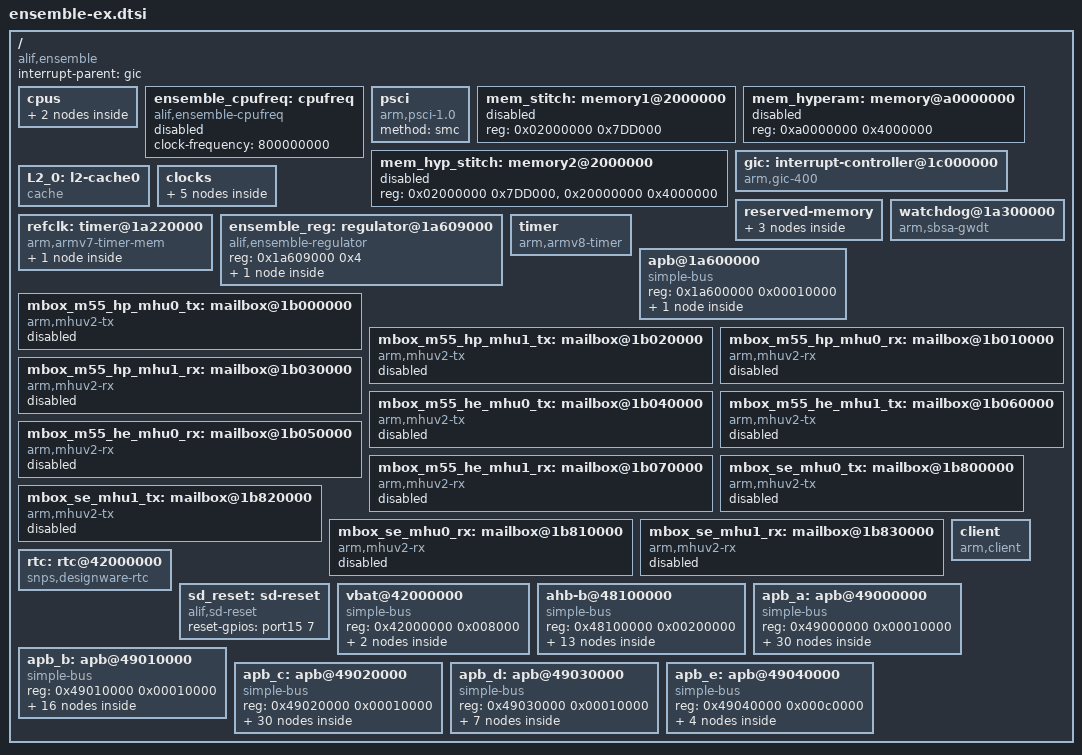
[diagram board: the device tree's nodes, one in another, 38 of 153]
// SPDX-License-Identifier: GPL-2.0+
/*
 * Copyright (C) 2025 Alif Semiconductor
 */
#include <dt-bindings/interrupt-controller/arm-gic.h>
#include <dt-bindings/pinctrl/alif,ensemble-pinfunc.h>
#include <dt-bindings/clock/alif,ensemble-clock.h>
#include <dt-bindings/gpio/gpio.h>
#include "devkit_ex_dct_defines.h"
/ {
	compatible = "alif,ensemble";
	interrupt-parent = <&gic>;
	#address-cells = <1>;
	#size-cells = <1>;

	cpus {
		#address-cells = <1>;
		#size-cells = <0>;

		cpu0: cpu@0 {
			compatible = "arm,armv8";
			reg = <0>;
			device_type = "cpu";
			enable-method = "psci";
			next-level-cache = <&L2_0>;
		};

		cpu1: cpu@1 {
			compatible = "arm,armv8";
			reg = <1>;
			device_type = "cpu";
			enable-method = "psci";
			next-level-cache = <&L2_0>;
			status = "disabled";
		};
	};

	ensemble_cpufreq: cpufreq {
		compatible = "alif,ensemble-cpufreq";
		clock-frequency = <800000000>;  /* 800 MHz boot default */
		status = "disabled";
	};

	psci {
		compatible = "arm,psci-1.0";
		method = "smc";
	};

	mem_stitch: memory1@2000000 {
		device_type = "memory";
		reg = <0x02000000 0x7DD000>;
		status = "disabled";
			/* 0x1000 @ 0x027DD000 reserved for IPC shared memory */
			/* 0x20000 @ 0x027DE000 reserved for arm-tf */
			/* 0x1000 @ 0x027FE000 reserved for MHU services */
	};

	mem_hyperam: memory@a0000000 {
		device_type = "memory";
		reg = <0xa0000000 0x4000000>;
		status = "disabled";
			/* 0x1000 @ 0x027DD000 reserved for IPC shared memory */
			/* 0x20000 @ 0x027DE000 reserved for arm-tf */
			/* 0x1000 @ 0x027FE000 reserved for MHU services */
	};

	mem_hyp_stitch: memory2@2000000 {
		device_type = "memory";
		reg = <0x02000000 0x7DD000>,
			<0x20000000 0x4000000>;
		status = "disabled";
			/* 0x1000 @ 0x027DD000 reserved for IPC shared memory */
			/* 0x20000 @ 0x027DE000 reserved for arm-tf */
			/* 0x1000 @ 0x027FE000 reserved for MHU services */
	};

	gic: interrupt-controller@1c000000 {
		compatible = "arm,gic-400";
		#interrupt-cells = <3>;
		#address-cells = <0>;
		interrupt-controller;
		reg =	<0x1c010000 0x1000>,
			<0x1c02f000 0x2000>,
			<0x1c04f000 0x1000>,
			<0x1c06f000 0x2000>;
		interrupts = <1 9 0xf08>;
	};

	L2_0: l2-cache0 {
		compatible = "cache";
	};

	clocks {
		hfxo: clock-38m4 {
			compatible = "fixed-clock";
			#clock-cells = <0>;
			clock-frequency = <38400000>;
			clock-output-names = "hfxo";
		};

		pll_clk1: clock-800m {
			compatible = "fixed-clock";
			#clock-cells = <0>;
			clock-frequency = <800000000>;
			clock-output-names = "pll_clk1";
		};

		pll_clk3: clock-480m {
			compatible = "fixed-clock";
			#clock-cells = <0>;
			clock-frequency = <480000000>;
			clock-output-names = "pll_clk3";
		};

		ext_clk: clock-20m {
			compatible = "fixed-clock";
			#clock-cells = <0>;
			clock-frequency = <20000000>;
			clock-output-names = "ext_clk";
		};
		wm8904_mclk: clock-12m288 {
			compatible = "fixed-clock";
			#clock-cells = <0>;
			clock-frequency = <12288000>;
			clock-output-names = "wm8904_mclk";
		};
	};

	reserved-memory {
		#address-cells = <1>;
		#size-cells = <1>;
		ranges;

		/* Reserved memory for Ethos-U85 NPU operations - WITHIN HyperRAM */
		ethosu_reserved: ethosu@a2000000 {
			compatible = "shared-dma-pool";
			reg = <0xa2000000 0x1000000>; /* 16MB within HyperRAM */
			no-map;
		};

		/* Ethos-U85 dedicated SRAM pool */
		ethosu_sram: ethosu_sram@a3000000 {
			compatible = "shared-dma-pool";
			reg = <0xa3000000 0x60000>; /* 384KB SRAM within HyperRAM */
			no-map;
		};

		/* CPI frame buffer pool in on-chip SRAM (4 x 560x560 RAW10 frames) */
		cpi_buf: cpi-frame-buffer@2000000 {
			compatible = "shared-dma-pool";
			reg = <0x02000000 0x300000>; /* 3MB from SRAM */
			no-map;
		};

	};

	refclk: timer@1a220000 {
		compatible = "arm,armv7-timer-mem";
		reg = <0x1a220000  0x1000>;
		clock-frequency = <100000000>;
		#address-cells = <1>;
		#size-cells = <1>;
		ranges;

		frame@1a230000 {
			frame-number = <0>;
			interrupts = <0 2 0xf04>;
			reg = <0x1a230000 0x1000>;
		};
	};

	ensemble_reg: regulator@1a609000 {
		compatible = "alif,ensemble-regulator";
		reg = <0x1a609000 0x4>;
		flexio_reg: ensemble_flexio {
			regulator-name = "ensemble_flexio";
			regulator-min-microvolt = <1800000>;
			regulator-max-microvolt = <3300000>;
			regulator-initial-mode = <0x4>;
			regulator-always-on;
		};
	};

	watchdog@1a300000 {
		compatible = "arm,sbsa-gwdt";
		reg = <0x1a300000 0x1000>,
			<0x1a310000 0x1000>;
		clocks = <&psclks ENSEMBLE_SYST_PCLK>;
		clock-names = "syst_pclk";
		interrupt-parent = <&gic>;
		interrupts = <0 32 4>;
		timeout-sec = <100>;
	};

	timer {
		compatible = "arm,armv8-timer";
		interrupts =	<GIC_PPI 13 (GIC_CPU_MASK_SIMPLE(2) |
					 IRQ_TYPE_LEVEL_LOW)>,
				<GIC_PPI 14 (GIC_CPU_MASK_SIMPLE(2) |
					 IRQ_TYPE_LEVEL_LOW)>,
				<GIC_PPI 11 (GIC_CPU_MASK_SIMPLE(2) |
					 IRQ_TYPE_LEVEL_LOW)>,
				<GIC_PPI 10 (GIC_CPU_MASK_SIMPLE(2) |
					 IRQ_TYPE_LEVEL_LOW)>;
		arm,cpu-registers-not-fw-configured;
	};

	apb@1a600000 {
		compatible = "simple-bus";
		#address-cells = <1>;
		#size-cells = <1>;
		reg = <0x1a600000 0x00010000>;
		ranges = <>;

		pinmux: pinctrl@1a603000 {
			compatible = "alif,ensemble-pinctrl";
			reg = <0x1a603000 0x00001000>;
		};
	};

	mbox_m55_hp_mhu0_tx: mailbox@1b000000 {
		compatible = "arm,mhuv2-tx","arm,primecell";
		reg = <0x1b000000 0x1000>;
		clocks = <&psclks ENSEMBLE_SYST_ACLK>;
		clock-names = "apb_pclk";
		interrupts = <0 11 4>;
		interrupt-names = "mhu_tx";
		arm,mhuv2-protocols = <1 1>, <1 1>;
		#mbox-cells = <2>;
		mbox-name = "arm-m55_hp-mhu0_tx";
		status = "disabled";
	};
	mbox_m55_hp_mhu1_tx: mailbox@1b020000 {
		compatible = "arm,mhuv2-tx","arm,primecell";
		reg = <0x1b020000 0x1000>;
		clocks = <&psclks ENSEMBLE_SYST_ACLK>;
		clock-names = "apb_pclk";
		interrupts = <0 46 4>;
		interrupt-names = "mhu_tx";
		arm,mhuv2-protocols = <1 1>, <1 1>;
		#mbox-cells = <2>;
		mbox-name = "arm-m55_hp-mhu1_tx";
		status = "disabled";
	};
	mbox_m55_hp_mhu0_rx: mailbox@1b010000 {
		compatible = "arm,mhuv2-rx","arm,primecell";
		reg = <0x1b010000 0x1000>;
		clocks = <&psclks ENSEMBLE_SYST_ACLK>;
		clock-names = "apb_pclk";
		interrupts = <0 12 4>;
		interrupt-names = "mhu_rx";
		arm,mhuv2-protocols = <1 1>, <1 1>;
		#mbox-cells = <2>;
		mbox-name = "arm-m55_hp-mhu0_rx";
		status = "disabled";
	};
	mbox_m55_hp_mhu1_rx: mailbox@1b030000 {
		compatible = "arm,mhuv2-rx","arm,primecell";
		reg = <0x1b030000 0x1000>;
		clocks = <&psclks ENSEMBLE_SYST_ACLK>;
		clock-names = "apb_pclk";
		interrupts = <0 47 4>;
		interrupt-names = "mhu_rx";
		arm,mhuv2-protocols = <1 1>, <1 1>;
		#mbox-cells = <2>;
		mbox-name = "arm-m55_hp-mhu1_rx";
		status = "disabled";
	};

	mbox_m55_he_mhu0_tx: mailbox@1b040000 {
		compatible = "arm,mhuv2-tx","arm,primecell";
		reg = <0x1b040000 0x1000>;
		clocks = <&psclks ENSEMBLE_SYST_ACLK>;
		clock-names = "apb_pclk";
		interrupts = <0 13 4>;
		interrupt-names = "mhu_tx";
		arm,mhuv2-protocols = <1 1>, <1 1>;
		#mbox-cells = <2>;
		mbox-name = "arm-m55_he-mhu0_tx";
		status = "disabled";
	};
	mbox_m55_he_mhu1_tx: mailbox@1b060000 {
		compatible = "arm,mhuv2-tx","arm,primecell";
		reg = <0x1b060000 0x1000>;
		clocks = <&psclks ENSEMBLE_SYST_ACLK>;
		clock-names = "apb_pclk";
		interrupts = <0 48 4>;
		interrupt-names = "mhu_tx";
		arm,mhuv2-protocols = <1 1>, <1 1>;
		#mbox-cells = <2>;
		mbox-name = "arm-m55_he-mhu1_tx";
		status = "disabled";
	};
	mbox_m55_he_mhu0_rx: mailbox@1b050000 {
		compatible = "arm,mhuv2-rx","arm,primecell";
		reg = <0x1b050000 0x1000>;
		clocks = <&psclks ENSEMBLE_SYST_ACLK>;
		clock-names = "apb_pclk";
		interrupts = <0 14 4>;
		interrupt-names = "mhu_rx";
		arm,mhuv2-protocols = <1 1>, <1 1>;
		#mbox-cells = <2>;
		mbox-name = "arm-m55_he-mhu0_rx";
		status = "disabled";
	};
	mbox_m55_he_mhu1_rx: mailbox@1b070000 {
		compatible = "arm,mhuv2-rx","arm,primecell";
		reg = <0x1b070000 0x1000>;
		clocks = <&psclks ENSEMBLE_SYST_ACLK>;
		clock-names = "apb_pclk";
		interrupts = <0 49 4>;
		interrupt-names = "mhu_rx";
		arm,mhuv2-protocols = <1 1>, <1 1>;
		#mbox-cells = <2>;
		mbox-name = "arm-m55_he-mhu1_rx";
		status = "disabled";
	};
	mbox_se_mhu0_tx: mailbox@1b800000 {
		#mbox-cells = <2>;
		compatible = "arm,mhuv2-tx","arm,primecell";
		reg = <0x1b800000 0x1000>;
		clocks = <&psclks ENSEMBLE_SYST_ACLK>;
		clock-names = "apb_pclk";
		interrupts = <0 9 4>;
		interrupt-names = "mhu_tx";
		arm,mhuv2-protocols = <1 1>, <1 1>;
		mbox-name = "arm-se-mhu0_tx";
		status = "disabled";
	};

	mbox_se_mhu1_tx: mailbox@1b820000 {
		compatible = "arm,mhuv2-tx","arm,primecell";
		reg = <0x1b820000 0x1000>;
		clocks = <&psclks ENSEMBLE_SYST_ACLK>;
		clock-names = "apb_pclk";
		interrupts = <0 44 4>;
		interrupt-names = "mhu_tx";
		arm,mhuv2-protocols = <1 1>, <1 1>;
		#mbox-cells = <2>;
		mbox-name = "arm-se-mhu1_tx";
		status = "disabled";
	};
	mbox_se_mhu0_rx: mailbox@1b810000 {
		#mbox-cells = <2>;
		compatible = "arm,mhuv2-rx","arm,primecell";
		reg = <0x1b810000 0x1000>;
		clocks = <&psclks ENSEMBLE_SYST_ACLK>;
		clock-names = "apb_pclk";
		interrupts = <0 10 4>;
		interrupt-names = "mhu_rx";
		arm,mhuv2-protocols = <1 1>, <1 1>;
		mbox-name = "arm-se-mhu0_rx";
		status = "disabled";
	};
	mbox_se_mhu1_rx: mailbox@1b830000 {
		compatible = "arm,mhuv2-rx","arm,primecell";
		reg = <0x1b830000 0x1000>;
		clocks = <&psclks ENSEMBLE_SYST_ACLK>;
		clock-names = "apb_pclk";
		interrupts = <0 45 4>;
		interrupt-names = "mhu_rx";
		arm,mhuv2-protocols = <1 1>, <1 1>;
		#mbox-cells = <2>;
		mbox-name = "arm-se-mhu1_rx";
		status = "disabled";
	};

	client {
		compatible = "arm,client";
		mbox-names = "txdb0", "txdb1",
			     "rxdb0", "rxdb1",
			     "txdb2", "txdb3",
			     "rxdb2", "rxdb3",
			     "txdb4", "txdb5",
			     "rxdb4", "rxdb5";
		mboxes =  <&mbox_m55_hp_mhu0_tx 0 0>,
			  <&mbox_m55_hp_mhu1_tx 0 0>,
			  <&mbox_m55_hp_mhu0_rx 0 0>,
			  <&mbox_m55_hp_mhu1_rx 0 0>,
			  <&mbox_m55_he_mhu0_tx 0 0>,
			  <&mbox_m55_he_mhu1_tx 0 0>,
			  <&mbox_m55_he_mhu0_rx 0 0>,
			  <&mbox_m55_he_mhu1_rx 0 0>,
			  <&mbox_se_mhu0_tx 0 0>,
			  <&mbox_se_mhu1_tx 0 0>,
			  <&mbox_se_mhu0_rx 0 0>,
			  <&mbox_se_mhu1_rx 0 0>;
	};

	rtc: rtc@42000000 {
		compatible = "snps,designware-rtc";
		reg = <0x42000000 0x100>;
		interrupts = <GIC_SPI 339  IRQ_TYPE_LEVEL_HIGH>;
		clocks = <&psclks ENSEMBLE_S32K_CLK>,
			<&psclks ENSEMBLE_SYST_PCLK>;
		clock-names = "timer", "pclk";
	};

	sd_reset: sd-reset {
		compatible = "alif,sd-reset";
		reset-gpios = <&port15 7 GPIO_ACTIVE_HIGH>;
	};

	vbat@42000000 {
		compatible = "simple-bus";
		#address-cells = <1>;
		#size-cells = <1>;
		reg = <0x42000000 0x008000>;
		ranges = <>;

		lpgpio: gpio@42002000 {
			#address-cells = <1>;
			#size-cells = <0>;
			compatible = "snps,dw-apb-gpio";
			reg = <0x42002000 0x1000>;

			port16: gpio-port@0 {
				compatible = "snps,dw-apb-gpio-port";
				gpio-port;
				#gpio-cells = <2>;
				snps,nr-gpios = <8>;
				reg = <0>;
				interrupt-controller;
				#interrupt-cells = <2>;
				interrupt-parent = <&gic>;
				interrupts = <GIC_SPI 160 IRQ_TYPE_LEVEL_HIGH>,
					     <GIC_SPI 161 IRQ_TYPE_LEVEL_HIGH>,
					     <GIC_SPI 162 IRQ_TYPE_LEVEL_HIGH>,
					     <GIC_SPI 163 IRQ_TYPE_LEVEL_HIGH>,
					     <GIC_SPI 164 IRQ_TYPE_LEVEL_HIGH>,
					     <GIC_SPI 165 IRQ_TYPE_LEVEL_HIGH>,
					     <GIC_SPI 166 IRQ_TYPE_LEVEL_HIGH>,
					     <GIC_SPI 167 IRQ_TYPE_LEVEL_HIGH>;
			};
		};
	};

	ahb-b@48100000 {
		compatible = "simple-bus";
		#address-cells = <1>;
		#size-cells = <1>;
		reg = <0x48100000 0x00200000>;
		ranges = <>;

		utimer: timer@48000000 {
			compatible = "alif,alif-utimer";
			clocks = <&psclks ENSEMBLE_SYST_ACLK>;
			clock-names = "axi_clk" ;
			reg = <0x48000000 0x100000>;
			interrupt-parent = <&gic>;
			interrupts =    <GIC_SPI 366 IRQ_TYPE_EDGE_RISING>,
					<GIC_SPI 367 IRQ_TYPE_EDGE_RISING>,
					<GIC_SPI 368 IRQ_TYPE_EDGE_RISING>,
					<GIC_SPI 369 IRQ_TYPE_EDGE_RISING>,
					<GIC_SPI 370 IRQ_TYPE_EDGE_RISING>,
					<GIC_SPI 371 IRQ_TYPE_EDGE_RISING>,
					<GIC_SPI 372 IRQ_TYPE_EDGE_RISING>,
					<GIC_SPI 373 IRQ_TYPE_EDGE_RISING>,
					<GIC_SPI 374 IRQ_TYPE_EDGE_RISING>,
					<GIC_SPI 375 IRQ_TYPE_EDGE_RISING>,
					<GIC_SPI 376 IRQ_TYPE_EDGE_RISING>,
					<GIC_SPI 377 IRQ_TYPE_EDGE_RISING>,
					<GIC_SPI 378 IRQ_TYPE_EDGE_RISING>,
					<GIC_SPI 379 IRQ_TYPE_EDGE_RISING>,
					<GIC_SPI 380 IRQ_TYPE_EDGE_RISING>,
					<GIC_SPI 381 IRQ_TYPE_EDGE_RISING>,
					<GIC_SPI 382 IRQ_TYPE_EDGE_RISING>,
					<GIC_SPI 383 IRQ_TYPE_EDGE_RISING>,
					<GIC_SPI 384 IRQ_TYPE_EDGE_RISING>,
					<GIC_SPI 385 IRQ_TYPE_EDGE_RISING>,
					<GIC_SPI 386 IRQ_TYPE_EDGE_RISING>,
					<GIC_SPI 387 IRQ_TYPE_EDGE_RISING>,
					<GIC_SPI 388 IRQ_TYPE_EDGE_RISING>,
					<GIC_SPI 389 IRQ_TYPE_EDGE_RISING>,
					<GIC_SPI 390 IRQ_TYPE_EDGE_RISING>,
					<GIC_SPI 391 IRQ_TYPE_EDGE_RISING>,
					<GIC_SPI 392 IRQ_TYPE_EDGE_RISING>,
					<GIC_SPI 393 IRQ_TYPE_EDGE_RISING>,
					<GIC_SPI 394 IRQ_TYPE_EDGE_RISING>,
					<GIC_SPI 395 IRQ_TYPE_EDGE_RISING>,
					<GIC_SPI 396 IRQ_TYPE_EDGE_RISING>,
					<GIC_SPI 397 IRQ_TYPE_EDGE_RISING>,
					<GIC_SPI 398 IRQ_TYPE_EDGE_RISING>,
					<GIC_SPI 399 IRQ_TYPE_EDGE_RISING>,
					<GIC_SPI 400 IRQ_TYPE_EDGE_RISING>,
					<GIC_SPI 401 IRQ_TYPE_EDGE_RISING>,
					<GIC_SPI 402 IRQ_TYPE_EDGE_RISING>,
					<GIC_SPI 403 IRQ_TYPE_EDGE_RISING>,
					<GIC_SPI 404 IRQ_TYPE_EDGE_RISING>,
					<GIC_SPI 405 IRQ_TYPE_EDGE_RISING>,
					<GIC_SPI 406 IRQ_TYPE_EDGE_RISING>,
					<GIC_SPI 407 IRQ_TYPE_EDGE_RISING>,
					<GIC_SPI 408 IRQ_TYPE_EDGE_RISING>,
					<GIC_SPI 409 IRQ_TYPE_EDGE_RISING>,
					<GIC_SPI 410 IRQ_TYPE_EDGE_RISING>,
					<GIC_SPI 411 IRQ_TYPE_EDGE_RISING>,
					<GIC_SPI 412 IRQ_TYPE_EDGE_RISING>,
					<GIC_SPI 413 IRQ_TYPE_EDGE_RISING>,
					<GIC_SPI 414 IRQ_TYPE_EDGE_RISING>,
					<GIC_SPI 415 IRQ_TYPE_EDGE_RISING>,
					<GIC_SPI 416 IRQ_TYPE_EDGE_RISING>,
					<GIC_SPI 417 IRQ_TYPE_EDGE_RISING>,
					<GIC_SPI 418 IRQ_TYPE_EDGE_RISING>,
					<GIC_SPI 419 IRQ_TYPE_EDGE_RISING>,
					<GIC_SPI 420 IRQ_TYPE_EDGE_RISING>,
					<GIC_SPI 421 IRQ_TYPE_EDGE_RISING>,
					<GIC_SPI 422 IRQ_TYPE_EDGE_RISING>,
					<GIC_SPI 423 IRQ_TYPE_EDGE_RISING>,
					<GIC_SPI 424 IRQ_TYPE_EDGE_RISING>,
					<GIC_SPI 425 IRQ_TYPE_EDGE_RISING>,
					<GIC_SPI 426 IRQ_TYPE_EDGE_RISING>,
					<GIC_SPI 427 IRQ_TYPE_EDGE_RISING>,
					<GIC_SPI 428 IRQ_TYPE_EDGE_RISING>,
					<GIC_SPI 429 IRQ_TYPE_EDGE_RISING>,
					<GIC_SPI 430 IRQ_TYPE_EDGE_RISING>,
					<GIC_SPI 431 IRQ_TYPE_EDGE_RISING>,
					<GIC_SPI 432 IRQ_TYPE_EDGE_RISING>,
					<GIC_SPI 433 IRQ_TYPE_EDGE_RISING>,
					<GIC_SPI 434 IRQ_TYPE_EDGE_RISING>,
					<GIC_SPI 435 IRQ_TYPE_EDGE_RISING>,
					<GIC_SPI 436 IRQ_TYPE_EDGE_RISING>,
					<GIC_SPI 437 IRQ_TYPE_EDGE_RISING>,
					<GIC_SPI 438 IRQ_TYPE_EDGE_RISING>,
					<GIC_SPI 439 IRQ_TYPE_EDGE_RISING>,
					<GIC_SPI 440 IRQ_TYPE_EDGE_RISING>,
					<GIC_SPI 441 IRQ_TYPE_EDGE_RISING>,
					<GIC_SPI 442 IRQ_TYPE_EDGE_RISING>,
					<GIC_SPI 443 IRQ_TYPE_EDGE_RISING>,
					<GIC_SPI 444 IRQ_TYPE_EDGE_RISING>,
					<GIC_SPI 445 IRQ_TYPE_EDGE_RISING>,
					<GIC_SPI 446 IRQ_TYPE_EDGE_RISING>,
					<GIC_SPI 447 IRQ_TYPE_EDGE_RISING>,
					<GIC_SPI 448 IRQ_TYPE_EDGE_RISING>,
					<GIC_SPI 449 IRQ_TYPE_EDGE_RISING>,
					<GIC_SPI 450 IRQ_TYPE_EDGE_RISING>,
					<GIC_SPI 451 IRQ_TYPE_EDGE_RISING>,
					<GIC_SPI 452 IRQ_TYPE_EDGE_RISING>,
					<GIC_SPI 453 IRQ_TYPE_EDGE_RISING>,
					<GIC_SPI 454 IRQ_TYPE_EDGE_RISING>,
					<GIC_SPI 455 IRQ_TYPE_EDGE_RISING>,
					<GIC_SPI 456 IRQ_TYPE_EDGE_RISING>,
					<GIC_SPI 457 IRQ_TYPE_EDGE_RISING>,
					<GIC_SPI 458 IRQ_TYPE_EDGE_RISING>,
					<GIC_SPI 459 IRQ_TYPE_EDGE_RISING>,
					<GIC_SPI 460 IRQ_TYPE_EDGE_RISING>,
					<GIC_SPI 461 IRQ_TYPE_EDGE_RISING>;
			status = "disabled";
		};

		eth0: ethernet@48100000 {
			compatible = "snps,dwc-qos-ethernet-4.10";
			reg = <0x48100000 0x2000>;
			clock-names = "phy_ref_clk", "apb_pclk", "ptp_ref";
			clocks = <&psclks ENSEMBLE_ETH_CLK>,
				 <&psclks ENSEMBLE_ETH_CSR_CLK>,
				 <&psclks ENSEMBLE_100M_CLK>;
			interrupt-parent = <&gic>;
			interrupts = <GIC_SPI 137 IRQ_TYPE_LEVEL_HIGH>;
			max-speed = <100>;
			phy-handle = <&phy2>;
			phy-mode = "rmii";
			mac-address = [92 60 04 02 c3 e6];
			snps,force_thresh_dma_mode;
			status = "disabled";
			mdio{
				#address-cells = <0x1>;
				#size-cells = <0x0>;
				phy2: phy@0{
					compatible = "ethernet-phy-ieee802.3-c22";
					device_type = "ethernet-phy";
					reg = <0x1>;
				};
			};
		};

		adc_dac6: analog@4902a000 {
			compatible = "alif,adc-dac6";
			reg = <0x4902a000 0x2000>;
		};

		sdmmc: mmc@48102000 {
			compatible = "alif,ensemble-dwcmshc", "snps,dwcmshc-sdhci";
			reg = <0x48102000 0x1000>;
			interrupts = <GIC_SPI 27 IRQ_TYPE_LEVEL_HIGH>,
				     <GIC_SPI 28 IRQ_TYPE_LEVEL_HIGH>;
			clocks = <&psclks ENSEMBLE_SYST_HCLK>,
				 <&psclks ENSEMBLE_100M_CLK>;
			clock-names = "core", "bus";
			bus-width = <4>;
			max-frequency = <25000000>;
			no-hispeed;
			no-1-8-v;
			status = "disabled";
		};

		spi0: spi@48103000 {
			compatible = "snps,dwc-ssi-1.01a";
			reg = <0x48103000 0x1000>;
			num-cs = <1>;
			interrupts = <GIC_SPI 126 IRQ_TYPE_LEVEL_HIGH>;
			clocks = <&psclks ENSEMBLE_SPI0_SS_IN_VAL_MST_CLK>;
			clock-names = "ssi_clk" ;
			reg-io-width = <4>;
			spi-tx-bus-width = <1>;
			spi-rx-bus-width = <1>;
			status = "disabled";
		};

		spi1: spi@48104000 {
			compatible = "snps,dwc-ssi-1.01a";
			reg = <0x48104000 0x1000>;
			num-cs = <1>;
			interrupts = <GIC_SPI 127 IRQ_TYPE_LEVEL_HIGH>;
			clocks = <&psclks ENSEMBLE_SPI1_SS_IN_VAL_MST_CLK>;
			clock-names = "ssi_clk" ;
			reg-io-width = <4>;
			spi-tx-bus-width = <1>;
			spi-rx-bus-width = <1>;
			status = "disabled";
		};

		spi2: spi@48105000 {
			compatible = "snps,dwc-ssi-1.01a";
			reg = <0x48105000 0x1000>;
			num-cs = <1>;
			interrupts = <GIC_SPI 128 IRQ_TYPE_LEVEL_HIGH>;
			clocks = <&psclks ENSEMBLE_SPI2_SS_IN_VAL_MST_CLK>;
			clock-names = "ssi_clk" ;
			reg-io-width = <4>;
			spi-tx-bus-width = <1>;
			spi-rx-bus-width = <1>;
			status = "disabled";
		};

		spi3: spi@48106000 {
			compatible = "snps,dwc-ssi-1.01a";
			reg = <0x48106000 0x1000>;
			interrupts = <GIC_SPI 129 IRQ_TYPE_LEVEL_HIGH>;
			clocks = <&psclks ENSEMBLE_SPI3_SS_IN_VAL_MST_CLK>;
			clock-names = "ssi_clk" ;
			num-cs = <1>;
			reg-io-width = <4>;
			spi-tx-bus-width = <1>;
			spi-rx-bus-width = <1>;
			spi-max-frequency= <1000000>;
			status = "disabled";
		};

		crc: crc@48107000 {
			compatible = "alif,alif-crccode";
			reg = <0x48107000 0x1000>;
			clocks = <&psclks ENSEMBLE_SYST_HCLK>;
			clock-names = "ahb_clk";
		};

		hsusb: dwc3@48200000 {
			compatible = "alif,ensemble-usb3";
			#address-cells = <1>;
			#size-cells = <1>;
			ranges = <0x48200000 0x48200000 0x100000>;
			clock-names = "usb_clk", "dwc_clk";
			clocks = <&psclks ENSEMBLE_USB_CLK>,
				<&psclks ENSEMBLE_DWC_USB_CLK>;
			status = "disabled";
			dwc3: usb@48200000 {
				compatible = "snps","snps,dwc3";
				reg = <0x48200000 0x100000>;
				interrupts = <GIC_SPI 26 IRQ_TYPE_LEVEL_HIGH>;
				phy = <&psclks ENSEMBLE_USB_CLK>;
				phy-names = "usb2_phy";
				dr_mode = "peripheral";
				snps,hsphy_interface = "utmi";
				phy_type = "utmi_wide";
				maximum-speed = "high-speed";
				snps,dis_u3_susphy_quirk;
				snps,dis_u2_susphy_quirk;
				snps,incr-burst-type-adjustment = <1>, <4>, <8>, <16>;
				snps,quirk-frame-length-adjustment = <0x20>;
				snps,usb2-lpm-disable;
				status = "disabled";
			};
		};
	};

	apb_a: apb@49000000{
		compatible = "simple-bus";
		#address-cells = <1>;
		#size-cells = <1>;
		reg = <0x49000000 0x00010000>;
		ranges = <>;

		gpio0: gpio@49000000 {
			#address-cells = <1>;
			#size-cells = <0>;
			compatible = "snps,dw-apb-gpio";
			reg = <0x49000000 0x1000>;
			status = "disabled";

			port1: gpio-port@0 {
				compatible = "snps,dw-apb-gpio-port";
				gpio-port;
				#gpio-cells = <2>;
				snps,nr-gpios = <8>;
				reg = <0>;
				interrupt-controller;
				#interrupt-cells = <2>;
				interrupt-parent = <&gic>;
				interrupts = <GIC_SPI 168 IRQ_TYPE_LEVEL_HIGH>,
					     <GIC_SPI 169 IRQ_TYPE_LEVEL_HIGH>,
					     <GIC_SPI 170 IRQ_TYPE_LEVEL_HIGH>,
					     <GIC_SPI 171 IRQ_TYPE_LEVEL_HIGH>,
					     <GIC_SPI 172 IRQ_TYPE_LEVEL_HIGH>,
					     <GIC_SPI 173 IRQ_TYPE_LEVEL_HIGH>,
					     <GIC_SPI 174 IRQ_TYPE_LEVEL_HIGH>,
					     <GIC_SPI 175 IRQ_TYPE_LEVEL_HIGH>;
			};
		};

		gpio1: gpio@49001000 {
			#address-cells = <1>;
			#size-cells = <0>;
			compatible = "snps,dw-apb-gpio";
			reg = <0x49001000 0x1000>;
			status = "disabled";

			port2: gpio-port@0 {
				compatible = "snps,dw-apb-gpio-port";
				reg = <0>;
				gpio-port;
				#gpio-cells = <2>;
				snps,nr-gpios = <8>;
				interrupt-controller;
				#interrupt-cells = <2>;
				interrupt-parent = <&gic>;
				interrupts = <GIC_SPI 176 IRQ_TYPE_LEVEL_HIGH>,
					     <GIC_SPI 177 IRQ_TYPE_LEVEL_HIGH>,
					     <GIC_SPI 178 IRQ_TYPE_LEVEL_HIGH>,
					     <GIC_SPI 179 IRQ_TYPE_LEVEL_HIGH>,
					     <GIC_SPI 180 IRQ_TYPE_LEVEL_HIGH>,
					     <GIC_SPI 181 IRQ_TYPE_LEVEL_HIGH>,
					     <GIC_SPI 182 IRQ_TYPE_LEVEL_HIGH>,
					     <GIC_SPI 183 IRQ_TYPE_LEVEL_HIGH>;
			};
		};

		gpio2: gpio@49002000 {
			#address-cells = <1>;
			#size-cells = <0>;
			compatible = "snps,dw-apb-gpio";
			reg = <0x49002000 0x1000>;
			status = "disabled";

			port3: gpio-port@0 {
				compatible = "snps,dw-apb-gpio-port";
				gpio-port;
				#gpio-cells = <2>;
				snps,nr-gpios = <8>;
				reg = <0>;
				interrupt-controller;
				#interrupt-cells = <2>;
				interrupt-parent = <&gic>;
				interrupts = <GIC_SPI 184 IRQ_TYPE_LEVEL_HIGH>,
						<GIC_SPI 185 IRQ_TYPE_LEVEL_HIGH>,
						<GIC_SPI 186 IRQ_TYPE_LEVEL_HIGH>,
						<GIC_SPI 187 IRQ_TYPE_LEVEL_HIGH>,
						<GIC_SPI 188 IRQ_TYPE_LEVEL_HIGH>,
						<GIC_SPI 189 IRQ_TYPE_LEVEL_HIGH>,
						<GIC_SPI 190 IRQ_TYPE_LEVEL_HIGH>,
						<GIC_SPI 191 IRQ_TYPE_LEVEL_HIGH>;
			};
		};

		gpio3: gpio@49003000 {
			#address-cells = <1>;
			#size-cells = <0>;
			compatible = "snps,dw-apb-gpio";
			reg = <0x49003000 0x1000>;
			status = "disabled";

			port4: gpio-port@0 {
				compatible = "snps,dw-apb-gpio-port";
				reg = <0>;
				gpio-port;
				#gpio-cells = <2>;
				snps,nr-gpios = <8>;
				interrupt-controller;
				#interrupt-cells = <2>;
				interrupt-parent = <&gic>;
				interrupts = <GIC_SPI 192 IRQ_TYPE_LEVEL_HIGH>,
						<GIC_SPI 193 IRQ_TYPE_LEVEL_HIGH>,
						<GIC_SPI 194 IRQ_TYPE_LEVEL_HIGH>,
						<GIC_SPI 195 IRQ_TYPE_LEVEL_HIGH>,
						<GIC_SPI 196 IRQ_TYPE_LEVEL_HIGH>,
						<GIC_SPI 197 IRQ_TYPE_LEVEL_HIGH>,
						<GIC_SPI 198 IRQ_TYPE_LEVEL_HIGH>,
						<GIC_SPI 199 IRQ_TYPE_LEVEL_HIGH>;
			};
		};

		gpio4: gpio@49004000 {
			#address-cells = <1>;
			#size-cells = <0>;
			compatible = "snps,dw-apb-gpio";
			reg = <0x49004000 0x1000>;
			status = "disabled";

			port5: gpio-port@0 {
				compatible = "snps,dw-apb-gpio-port";
				reg = <0>;
				gpio-port;
				#gpio-cells = <2>;
				snps,nr-gpios = <8>;
				interrupt-controller;
				#interrupt-cells = <2>;
				interrupt-parent = <&gic>;
				interrupts = <GIC_SPI 200 IRQ_TYPE_LEVEL_HIGH>,
						<GIC_SPI 201 IRQ_TYPE_LEVEL_HIGH>,
						<GIC_SPI 202 IRQ_TYPE_LEVEL_HIGH>,
						<GIC_SPI 203 IRQ_TYPE_LEVEL_HIGH>,
						<GIC_SPI 204 IRQ_TYPE_LEVEL_HIGH>,
						<GIC_SPI 205 IRQ_TYPE_LEVEL_HIGH>,
						<GIC_SPI 206 IRQ_TYPE_LEVEL_HIGH>,
						<GIC_SPI 207 IRQ_TYPE_LEVEL_HIGH>;
			};
		};

		gpio5: gpio@49005000 {
			#address-cells = <1>;
			#size-cells = <0>;
			compatible = "snps,dw-apb-gpio";
			reg = <0x49005000 0x1000>;
			status = "disabled";

			port6: gpio-port@0 {
				compatible = "snps,dw-apb-gpio-port";
				reg = <0>;
				gpio-port;
				#gpio-cells = <2>;
				snps,nr-gpios = <8>;
				interrupt-controller;
				#interrupt-cells = <2>;
				interrupt-parent = <&gic>;
				interrupts = <GIC_SPI 208 IRQ_TYPE_LEVEL_HIGH>,
						<GIC_SPI 209 IRQ_TYPE_LEVEL_HIGH>,
						<GIC_SPI 210 IRQ_TYPE_LEVEL_HIGH>,
						<GIC_SPI 211 IRQ_TYPE_LEVEL_HIGH>,
						<GIC_SPI 212 IRQ_TYPE_LEVEL_HIGH>,
						<GIC_SPI 213 IRQ_TYPE_LEVEL_HIGH>,
						<GIC_SPI 214 IRQ_TYPE_LEVEL_HIGH>,
						<GIC_SPI 215 IRQ_TYPE_LEVEL_HIGH>;
			};
		};

		gpio6: gpio@49006000 {
			#address-cells = <1>;
			#size-cells = <0>;
			compatible = "snps,dw-apb-gpio";
			reg = <0x49006000 0x1000>;
			status = "okay";

			port7: gpio-port@0 {
				compatible = "snps,dw-apb-gpio-port";
				reg = <0>;
				gpio-port;
				#gpio-cells = <2>;
				snps,nr-gpios = <8>;
				interrupt-controller;
				#interrupt-cells = <2>;
				interrupt-parent = <&gic>;
				interrupts = <GIC_SPI 216 IRQ_TYPE_LEVEL_HIGH>,
						<GIC_SPI 217 IRQ_TYPE_LEVEL_HIGH>,
						<GIC_SPI 218 IRQ_TYPE_LEVEL_HIGH>,
						<GIC_SPI 219 IRQ_TYPE_LEVEL_HIGH>,
						<GIC_SPI 220 IRQ_TYPE_LEVEL_HIGH>,
						<GIC_SPI 221 IRQ_TYPE_LEVEL_HIGH>,
						<GIC_SPI 222 IRQ_TYPE_LEVEL_HIGH>,
						<GIC_SPI 223 IRQ_TYPE_LEVEL_HIGH>;
			};
		};

		gpio7: gpio@49007000 {
			#address-cells = <1>;
			#size-cells = <0>;
			compatible = "snps,dw-apb-gpio";
			reg = <0x49007000 0x1000>;
			status = "disabled";

			port8: gpio-port@0 {
				compatible = "snps,dw-apb-gpio-port";
				reg = <0>;
				gpio-port;
				#gpio-cells = <2>;
				snps,nr-gpios = <8>;
				interrupt-controller;
				#interrupt-cells = <2>;
				interrupt-parent = <&gic>;
				interrupts = <GIC_SPI 224 IRQ_TYPE_LEVEL_HIGH>,
						<GIC_SPI 225 IRQ_TYPE_LEVEL_HIGH>,
						<GIC_SPI 226 IRQ_TYPE_LEVEL_HIGH>,
						<GIC_SPI 227 IRQ_TYPE_LEVEL_HIGH>,
						<GIC_SPI 228 IRQ_TYPE_LEVEL_HIGH>,
						<GIC_SPI 229 IRQ_TYPE_LEVEL_HIGH>,
						<GIC_SPI 230 IRQ_TYPE_LEVEL_HIGH>,
						<GIC_SPI 231 IRQ_TYPE_LEVEL_HIGH>;
			};
		};

		gpio8: gpio@49008000 {
			#address-cells = <1>;
			#size-cells = <0>;
			compatible = "snps,dw-apb-gpio";
			reg = <0x49008000 0x1000>;
			status = "disabled";

			port9: gpio-port@0 {
				compatible = "snps,dw-apb-gpio-port";
				reg = <0>;
				gpio-port;
				#gpio-cells = <2>;
				snps,nr-gpios = <8>;
				interrupt-controller;
				#interrupt-cells = <2>;
				interrupt-parent = <&gic>;
				interrupts = <GIC_SPI 232 IRQ_TYPE_LEVEL_HIGH>,
						<GIC_SPI 233 IRQ_TYPE_LEVEL_HIGH>,
						<GIC_SPI 234 IRQ_TYPE_LEVEL_HIGH>,
						<GIC_SPI 235 IRQ_TYPE_LEVEL_HIGH>,
						<GIC_SPI 236 IRQ_TYPE_LEVEL_HIGH>,
						<GIC_SPI 237 IRQ_TYPE_LEVEL_HIGH>,
						<GIC_SPI 238 IRQ_TYPE_LEVEL_HIGH>,
						<GIC_SPI 239 IRQ_TYPE_LEVEL_HIGH>;
			};
		};

		gpio9: gpio@49009000 {
			#address-cells = <1>;
			#size-cells = <0>;
			compatible = "snps,dw-apb-gpio";
			reg = <0x49009000 0x1000>;
			status = "disabled";

			port10: gpio-port@0 {
				compatible = "snps,dw-apb-gpio-port";
				reg = <0>;
				gpio-port;
				#gpio-cells = <2>;
				snps,nr-gpios = <8>;
				interrupt-controller;
				#interrupt-cells = <2>;
				interrupt-parent = <&gic>;
				interrupts = <GIC_SPI 240 IRQ_TYPE_LEVEL_HIGH>,
						<GIC_SPI 241 IRQ_TYPE_LEVEL_HIGH>,
						<GIC_SPI 242 IRQ_TYPE_LEVEL_HIGH>,
						<GIC_SPI 243 IRQ_TYPE_LEVEL_HIGH>,
						<GIC_SPI 244 IRQ_TYPE_LEVEL_HIGH>,
						<GIC_SPI 245 IRQ_TYPE_LEVEL_HIGH>,
						<GIC_SPI 246 IRQ_TYPE_LEVEL_HIGH>,
						<GIC_SPI 247 IRQ_TYPE_LEVEL_HIGH>;
			};
		};

		gpio10: gpio@4900a000 {
			#address-cells = <1>;
			#size-cells = <0>;
			compatible = "snps,dw-apb-gpio";
			reg = <0x4900a000 0x1000>;
			status = "disabled";

			port11: gpio-port@0 {
				compatible = "snps,dw-apb-gpio-port";
				reg = <0>;
				gpio-port;
				#gpio-cells = <2>;
				snps,nr-gpios = <8>;
				interrupt-controller;
				#interrupt-cells = <2>;
				interrupt-parent = <&gic>;
				interrupts = <GIC_SPI 248 IRQ_TYPE_LEVEL_HIGH>,
						<GIC_SPI 249 IRQ_TYPE_LEVEL_HIGH>,
						<GIC_SPI 250 IRQ_TYPE_LEVEL_HIGH>,
						<GIC_SPI 251 IRQ_TYPE_LEVEL_HIGH>,
						<GIC_SPI 252 IRQ_TYPE_LEVEL_HIGH>,
						<GIC_SPI 253 IRQ_TYPE_LEVEL_HIGH>,
						<GIC_SPI 254 IRQ_TYPE_LEVEL_HIGH>,
						<GIC_SPI 255 IRQ_TYPE_LEVEL_HIGH>;
			};
		};

		gpio11: gpio@4900b000 {
			#address-cells = <1>;
			#size-cells = <0>;
			compatible = "snps,dw-apb-gpio";
			reg = <0x4900b000 0x1000>;
			status = "disabled";

			port12: gpio-port@0 {
				compatible = "snps,dw-apb-gpio-port";
				reg = <0>;
				gpio-port;
				#gpio-cells = <2>;
				snps,nr-gpios = <8>;
				interrupt-controller;
				#interrupt-cells = <2>;
				interrupt-parent = <&gic>;
				interrupts = <GIC_SPI 256 IRQ_TYPE_LEVEL_HIGH>,
						<GIC_SPI 257 IRQ_TYPE_LEVEL_HIGH>,
						<GIC_SPI 258 IRQ_TYPE_LEVEL_HIGH>,
						<GIC_SPI 259 IRQ_TYPE_LEVEL_HIGH>,
						<GIC_SPI 260 IRQ_TYPE_LEVEL_HIGH>,
						<GIC_SPI 261 IRQ_TYPE_LEVEL_HIGH>,
						<GIC_SPI 262 IRQ_TYPE_LEVEL_HIGH>,
						<GIC_SPI 263 IRQ_TYPE_LEVEL_HIGH>;
			};
		};

		gpio12: gpio@4900c000 {
			#address-cells = <1>;
			#size-cells = <0>;
			compatible = "snps,dw-apb-gpio";
			reg = <0x4900c000 0x1000>;
			status = "okay";

			port13: gpio-port@0 {
				compatible = "snps,dw-apb-gpio-port";
				reg = <0>;
				gpio-port;
				#gpio-cells = <2>;
				snps,nr-gpios = <8>;
				interrupt-controller;
				#interrupt-cells = <2>;
				interrupt-parent = <&gic>;
				interrupts = <GIC_SPI 264 IRQ_TYPE_LEVEL_HIGH>,
						<GIC_SPI 265 IRQ_TYPE_LEVEL_HIGH>,
						<GIC_SPI 266 IRQ_TYPE_LEVEL_HIGH>,
						<GIC_SPI 267 IRQ_TYPE_LEVEL_HIGH>,
						<GIC_SPI 268 IRQ_TYPE_LEVEL_HIGH>,
						<GIC_SPI 269 IRQ_TYPE_LEVEL_HIGH>,
						<GIC_SPI 270 IRQ_TYPE_LEVEL_HIGH>,
						<GIC_SPI 271 IRQ_TYPE_LEVEL_HIGH>;
			};
		};

		gpio13: gpio@4900d000 {
			#address-cells = <1>;
			#size-cells = <0>;
			compatible = "snps,dw-apb-gpio";
			reg = <0x4900d000 0x1000>;
			status = "disabled";

			port14: gpio-port@0 {
				compatible = "snps,dw-apb-gpio-port";
				reg = <0>;
				gpio-port;
				#gpio-cells = <2>;
				snps,nr-gpios = <8>;
				interrupt-controller;
				#interrupt-cells = <2>;
				interrupt-parent = <&gic>;
				interrupts = <GIC_SPI 272 IRQ_TYPE_LEVEL_HIGH>,
						<GIC_SPI 273 IRQ_TYPE_LEVEL_HIGH>,
						<GIC_SPI 274 IRQ_TYPE_LEVEL_HIGH>,
						<GIC_SPI 275 IRQ_TYPE_LEVEL_HIGH>,
						<GIC_SPI 276 IRQ_TYPE_LEVEL_HIGH>,
						<GIC_SPI 277 IRQ_TYPE_LEVEL_HIGH>,
						<GIC_SPI 278 IRQ_TYPE_LEVEL_HIGH>,
						<GIC_SPI 279 IRQ_TYPE_LEVEL_HIGH>;
			};
		};

		gpio14: gpio@4900e000 {
			#address-cells = <1>;
			#size-cells = <0>;
			compatible = "snps,dw-apb-gpio";
			reg = <0x4900e000 0x1000>;
			status = "okay";

			port15: gpio-port@0 {
				compatible = "snps,dw-apb-gpio-port";
				reg = <0>;
				gpio-port;
				#gpio-cells = <2>;
				snps,nr-gpios = <8>;
				interrupt-controller;
				#interrupt-cells = <2>;
				interrupt-parent = <&gic>;
				interrupts = <GIC_SPI 280 IRQ_TYPE_LEVEL_HIGH>,
						<GIC_SPI 281 IRQ_TYPE_LEVEL_HIGH>,
						<GIC_SPI 282 IRQ_TYPE_LEVEL_HIGH>,
						<GIC_SPI 283 IRQ_TYPE_LEVEL_HIGH>,
						<GIC_SPI 284 IRQ_TYPE_LEVEL_HIGH>,
						<GIC_SPI 285 IRQ_TYPE_LEVEL_HIGH>,
						<GIC_SPI 286 IRQ_TYPE_LEVEL_HIGH>,
						<GIC_SPI 287 IRQ_TYPE_LEVEL_HIGH>;
			};
		};

	};

	apb_b: apb@49010000 {
		compatible = "simple-bus";
		#address-cells = <1>;
		#size-cells = <1>;
		reg = <0x49010000 0x00010000>;
		ranges = <>;

		uart0: serial@49018000 {
			compatible = "alif,ensemble-dw-uart", "snps,dw-apb-uart";
			reg = <0x49018000 0x1000>;
			interrupts = <GIC_SPI 113 IRQ_TYPE_LEVEL_HIGH>;
			clocks = <&psclks ENSEMBLE_UART0_CLK>;
			clock-names = "baudclk";
			reg-shift = <2>;
			reg-io-width = <4>;
			status = "disabled";
		};

		uart1: serial@49019000 {
			compatible = "alif,ensemble-dw-uart", "snps,dw-apb-uart";
			reg = <0x49019000 0x1000>;
			interrupts = <GIC_SPI 114 IRQ_TYPE_LEVEL_HIGH>;
			clocks = <&psclks ENSEMBLE_UART1_CLK>;
			clock-names = "baudclk";
			reg-shift = <2>;
			reg-io-width = <4>;
			status = "disabled";
		};

		uart2: serial@4901a000 {
			compatible = "snps,dw-apb-uart";
			reg = <0x4901a000 0x1000>;
			interrupts = <GIC_SPI 115 IRQ_TYPE_LEVEL_HIGH>;
			clocks = <&psclks ENSEMBLE_UART2_CLK>;
			clock-names = "baudclk";
			reg-shift = <2>;
			reg-io-width = <4>;
			status = "disabled";
		};

		uart3: serial@4901b000 {
			compatible = "alif,ensemble-dw-uart", "snps,dw-apb-uart";
			reg = <0x4901b000 0x1000>;
			interrupts = <GIC_SPI 116 IRQ_TYPE_LEVEL_HIGH>;
			clocks = <&psclks ENSEMBLE_UART3_CLK>;
			clock-names = "baudclk";
			reg-shift = <2>;
			reg-io-width = <4>;
			status = "disabled";
		};

		uart4: serial@4901c000 {
			compatible = "snps,dw-apb-uart";
			reg = <0x4901c000 0x1000>;
			interrupts = <GIC_SPI 117 IRQ_TYPE_LEVEL_HIGH>;
			clocks = <&psclks ENSEMBLE_UART4_CLK>;
			clock-names = "baudclk";
			reg-shift = <2>;
			reg-io-width = <4>;
			status = "disabled";
		};

		uart5: serial@4901d000 {
			compatible = "alif,ensemble-dw-uart", "snps,dw-apb-uart";
			reg = <0x4901d000 0x1000>;
			interrupts = <GIC_SPI 118 IRQ_TYPE_LEVEL_HIGH>;
			clocks = <&psclks ENSEMBLE_UART5_CLK>;
			reg-shift = <2>;
			reg-io-width = <4>;
			status = "disabled";
		};

		uart6: serial@4901e000 {
			compatible = "alif,ensemble-dw-uart", "snps,dw-apb-uart";
			reg = <0x4901e000 0x1000>;
			interrupts = <GIC_SPI 119 IRQ_TYPE_LEVEL_HIGH>;
			clocks = <&psclks ENSEMBLE_UART6_CLK>;
			reg-shift = <2>;
			reg-io-width = <4>;
			status = "disabled";
		};

		uart7: serial@4901f000 {
			compatible = "alif,ensemble-dw-uart", "snps,dw-apb-uart";
			reg = <0x4901f000 0x1000>;
			interrupts = <GIC_SPI 120 IRQ_TYPE_LEVEL_HIGH>;
			clocks = <&psclks ENSEMBLE_UART7_CLK>;
			reg-shift = <2>;
			reg-io-width = <4>;
			status = "disabled";
		};

		i2c0: i2c@49010000 {
			compatible = "snps,designware-i2c";
			reg = <0x49010000 0x1000>;
			interrupt-parent = <&gic>;
			interrupts = <GIC_SPI 121 IRQ_TYPE_LEVEL_HIGH>;
			clocks = <&psclks ENSEMBLE_SYST_PCLK>;
			i2c-sda-hold-time-ns = <300>;
			i2c-sda-falling-time-ns = <300>;
			i2c-scl-falling-time-ns = <300>;
			status = "disabled";
		};

		i2c1: i2c@49011000 {
			compatible = "snps,designware-i2c";
			reg = <0x49011000 0x1000>;
			interrupt-parent = <&gic>;
			interrupts = <GIC_SPI 122 IRQ_TYPE_LEVEL_HIGH>;
			clocks = <&psclks ENSEMBLE_SYST_PCLK>;
			i2c-sda-hold-time-ns = <300>;
			i2c-sda-falling-time-ns = <300>;
			i2c-scl-falling-time-ns = <300>;
			status = "disabled";
		};

		i2c2: i2c@49012000 {
			compatible = "snps,designware-i2c";
			reg = <0x49012000 0x1000>;
			interrupt-parent = <&gic>;
			interrupts = <GIC_SPI 123 IRQ_TYPE_LEVEL_HIGH>;
			clocks = <&psclks ENSEMBLE_SYST_PCLK>;
			i2c-sda-hold-time-ns = <300>;
			i2c-sda-falling-time-ns = <300>;
			i2c-scl-falling-time-ns = <300>;
			status = "disabled";
		};

		i2c3: i2c@49013000 {
			compatible = "snps,designware-i2c";
			reg = <0x49013000 0x1000>;
			interrupt-parent = <&gic>;
			interrupts = <GIC_SPI 124 IRQ_TYPE_LEVEL_HIGH>;
			clocks = <&psclks ENSEMBLE_SYST_PCLK>;
			i2c-sda-hold-time-ns = <300>;
			i2c-sda-falling-time-ns = <300>;
			i2c-scl-falling-time-ns = <300>;
			status = "disabled";
		};

		i2s0: i2s@49014000 {
			compatible = "snps,designware-i2s";
			reg = <0x49014000 0x1000>;
			clocks = <&psclks ENSEMBLE_I2S0_CLK>,
				<&psclks ENSEMBLE_I2S0_BIT_CLK>;
			clock-names = "pclk","i2sclk";
			#sound-dai-cells = <0>;
			interrupts = <GIC_SPI 130 IRQ_TYPE_LEVEL_HIGH>;
			status = "disabled";
		};

		i2s1: i2s@49015000 {
			compatible = "snps,designware-i2s";
			reg = <0x49015000 0x1000>;
			clocks = <&psclks ENSEMBLE_I2S1_CLK>,
				<&psclks ENSEMBLE_I2S1_BIT_CLK>;
			clock-names = "pclk","i2sclk";
			#sound-dai-cells = <0>;
			interrupts = <GIC_SPI 131 IRQ_TYPE_LEVEL_HIGH>;
			status = "disabled";
		};

		i2s2: i2s@49016000 {
			compatible = "snps,designware-i2s";
			reg = <0x49016000 0x1000>;
			clocks = <&psclks ENSEMBLE_I2S2_CLK>,
				<&psclks ENSEMBLE_I2S2_BIT_CLK>;
			clock-names = "pclk","i2sclk";
			#sound-dai-cells = <0>;
			interrupts = <GIC_SPI 132 IRQ_TYPE_LEVEL_HIGH>;
			status = "disabled";
		};

		i2s3: i2s@49017000 {
			compatible = "snps,designware-i2s";
			reg = <0x49017000 0x1000>;
			clocks = <&psclks ENSEMBLE_I2S3_CLK>,
				<&psclks ENSEMBLE_I2S3_BIT_CLK>;
			clock-names = "pclk","i2sclk";
			#sound-dai-cells = <0>;
/*			interrupts = <GIC_SPI 133 IRQ_TYPE_LEVEL_HIGH>;*/
			dmas = <&event_router 31 1>,
				 <&event_router 27 1>;
			dma-names = "tx","rx";
			status = "disabled";
		};

	};

	apb_c: apb@49020000 {
		compatible = "simple-bus";
		#address-cells = <1>;
		#size-cells = <1>;
		reg = <0x49020000 0x00010000>;
		ranges = <>;


		pdm0: sound@4902d000 {
			compatible = "alif,alif-pcm";
			reg = <0x4902d000 0x1000>;
			clocks = <&psclks ENSEMBLE_SYST_PCLK>,
				<&psclks ENSEMBLE_PDM_CLK>;
			clock-names = "pclk", "pdm_clk";
			interrupt-parent = <&gic>;
			interrupts = <0 134 IRQ_TYPE_LEVEL_HIGH>;
			status = "disabled";
		};

		pcmcard: audio-codec@4902d800 {
			compatible = "alif,alif-pcm-card";
			reg = <0x4902d800 0x1000>;
			clocks = <&psclks ENSEMBLE_SYST_PCLK>;
		};

		hwsem0: hwlock@4902e000 {
			compatible = "alif,hwsem";
			reg = <0x4902e000 0x4>;
			reg-names = "hwsem_base";
			interrupt-parent = <&gic>;
			interrupts = <0 30 4>;
			clocks = <&psclks ENSEMBLE_SYST_PCLK>;
			clock-names = "syst_pclk" ;
			status = "disabled";
		};

		hwsem1: hwlock@4902e010 {
			compatible = "alif,hwsem";
			reg = <0x4902e010 0x4>;
			reg-names = "hwsem_base";
			interrupt-parent = <&gic>;
			interrupts = <0 31 4>;
			clocks = <&psclks ENSEMBLE_SYST_PCLK>;
			clock-names = "syst_pclk" ;
			status = "disabled";
		};

		hwsem2: hwlock@4902e020 {
			compatible = "alif,hwsem";
			reg = <0x4902e020 0x4>;
			reg-names = "hwsem_base";
			interrupt-parent = <&gic>;
			interrupts = <0 96 4>;
			clocks = <&psclks ENSEMBLE_SYST_PCLK>;
			clock-names = "syst_pclk" ;
			status = "disabled";
		};
		hwsem3: hwlock@4902e030 {
			compatible = "alif,hwsem";
			reg = <0x4902e030 0x4>;
			reg-names = "hwsem_base";
			interrupt-parent = <&gic>;
			interrupts = <0 97 4>;
			clocks = <&psclks ENSEMBLE_SYST_PCLK>;
			clock-names = "syst_pclk" ;
			status = "disabled";
		};

		hwsem4: hwlock@4902e040 {
			compatible = "alif,hwsem";
			reg = <0x4902e040 0x4>;
			reg-names = "hwsem_base";
			interrupt-parent = <&gic>;
			interrupts = <0 98 4>;
			clocks = <&psclks ENSEMBLE_SYST_PCLK>;
			clock-names = "syst_pclk" ;
			status = "disabled";
		};

		hwsem5: hwlock@4902e050 {
			compatible = "alif,hwsem";
			reg = <0x4902e050 0x4>;
			reg-names = "hwsem_base";
			interrupt-parent = <&gic>;
			interrupts = <0 99 4>;
			clocks = <&psclks ENSEMBLE_SYST_PCLK>;
			clock-names = "syst_pclk" ;
			status = "disabled";
		};

		hwsem6: hwlock@4902e060 {
			compatible = "alif,hwsem";
			reg = <0x4902e060 0x4>;
			reg-names = "hwsem_base";
			interrupt-parent = <&gic>;
			interrupts = <0 100 4>;
			clocks = <&psclks ENSEMBLE_SYST_PCLK>;
			clock-names = "syst_pclk" ;
			status = "disabled";
		};

		hwsem7: hwlock@4902e070 {
			compatible = "alif,hwsem";
			reg = <0x4902e070 0x4>;
			reg-names = "hwsem_base";
			interrupt-parent = <&gic>;
			interrupts = <0 101 4>;
			clocks = <&psclks ENSEMBLE_SYST_PCLK>;
			clock-names = "syst_pclk" ;
			status = "disabled";
		};

		hwsem8: hwlock@4902e080 {
			compatible = "alif,hwsem";
			reg = <0x4902e080 0x4>;
			reg-names = "hwsem_base";
			interrupt-parent = <&gic>;
			interrupts = <0 102 4>;
			clocks = <&psclks ENSEMBLE_SYST_PCLK>;
			clock-names = "syst_pclk" ;
			status = "disabled";
		};

		hwsem9: hwlock@4902e090 {
			compatible = "alif,hwsem";
			reg = <0x4902e090 0x4>;
			reg-names = "hwsem_base";
			interrupt-parent = <&gic>;
			interrupts = <0 103 4>;
			clocks = <&psclks ENSEMBLE_SYST_PCLK>;
			clock-names = "syst_pclk" ;
			status = "disabled";
		};

		hwsem10: hwlock@4902e0a0 {
			compatible = "alif,hwsem";
			reg = <0x4902e0a0 0x4>;
			reg-names = "hwsem_base";
			interrupt-parent = <&gic>;
			interrupts = <0 104 4>;
			clocks = <&psclks ENSEMBLE_SYST_PCLK>;
			clock-names = "syst_pclk" ;
			status = "disabled";
		};

		hwsem11: hwlock@4902e0b0 {
			compatible = "alif,hwsem";
			reg = <0x4902e0b0 0x4>;
			reg-names = "hwsem_base";
			interrupt-parent = <&gic>;
			interrupts = <0 105 4>;
			clocks = <&psclks ENSEMBLE_SYST_PCLK>;
			clock-names = "syst_pclk" ;
			status = "disabled";
		};

		hwsem12: hwlock@4902e0c0 {
			compatible = "alif,hwsem";
			reg = <0x4902e0c0 0x4>;
			reg-names = "hwsem_base";
			interrupt-parent = <&gic>;
			interrupts = <0 106 4>;
			clocks = <&psclks ENSEMBLE_SYST_PCLK>;
			clock-names = "syst_pclk" ;
			status = "disabled";
		};

		hwsem13: hwlock@4902e0d0 {
			compatible = "alif,hwsem";
			reg = <0x4902e0d0 0x4>;
			reg-names = "hwsem_base";
			interrupt-parent = <&gic>;
			interrupts = <0 107 4>;
			clocks = <&psclks ENSEMBLE_SYST_PCLK>;
			clock-names = "syst_pclk" ;
			status = "disabled";
		};

		hwsem14: hwlock@4902e0e0 {
			compatible = "alif,hwsem";
			reg = <0x4902e0e0 0x4>;
			reg-names = "hwsem_base";
			interrupt-parent = <&gic>;
			interrupts = <0 108 4>;
			clocks = <&psclks ENSEMBLE_SYST_PCLK>;
			clock-names = "syst_pclk" ;
			status = "disabled";
		};

		hwsem15: hwlock@4902e0f0 {
			compatible = "alif,hwsem";
			reg = <0x4902e0f0 0x4>;
			reg-names = "hwsem_base";
			interrupt-parent = <&gic>;
			interrupts = <0 109 4>;
			clocks = <&psclks ENSEMBLE_SYST_PCLK>;
			clock-names = "syst_pclk" ;
			status = "disabled";
		};

		adc12_0: adc@49020000 {
			compatible = "alif,adc-dev";
			reg-names = "adc_base", "cmp_base";
			reg = <0x49020000 0x100>,
				<0x49023000 0x10>;
			interrupt-parent = <&gic>;
			interrupts = <0 140 IRQ_TYPE_LEVEL_HIGH>,
				     <0 143 IRQ_TYPE_LEVEL_HIGH>,
				     <0 146 IRQ_TYPE_LEVEL_HIGH>,
				     <0 149 IRQ_TYPE_LEVEL_HIGH>;
			clocks = <&psclks ENSEMBLE_ADC120_CLK>;
			clock-names = "adc_clk";
			status = "disabled";
		};

		adc12_1: adc@49021000 {
			compatible = "alif,adc-dev";
			reg-names = "adc_base";
			reg = <0x49021000 0x100>;
			interrupt-parent = <&gic>;
			interrupts = <0 141 IRQ_TYPE_LEVEL_HIGH>,
				     <0 144 IRQ_TYPE_LEVEL_HIGH>,
				     <0 147 IRQ_TYPE_LEVEL_HIGH>,
				     <0 150 IRQ_TYPE_LEVEL_HIGH>;
			clocks = <&psclks ENSEMBLE_ADC121_CLK>;
			clock-names = "adc_clk";
			status = "disabled";
		};

		adc12_2: adc@49022000 {
			compatible = "alif,adc-dev";
			reg-names = "adc_base";
			reg = <0x49022000 0x100>;
			interrupt-parent = <&gic>;
			interrupts = <0 142 IRQ_TYPE_LEVEL_HIGH>,
				     <0 145 IRQ_TYPE_LEVEL_HIGH>,
				     <0 148 IRQ_TYPE_LEVEL_HIGH>,
				     <0 151 IRQ_TYPE_LEVEL_HIGH>;
			clocks = <&psclks ENSEMBLE_ADC122_CLK>;
			clock-names = "adc_clk";
			status = "disabled";
		};

		adc24: adc@49027000 {
			compatible = "alif,adc-dev";
			reg-names = "adc_base", "cmp_base";
			reg = <0x49027000 0x100>,
				<0x49023000 0x10>;
			interrupt-parent = <&gic>;
			interrupts = <0 152 IRQ_TYPE_LEVEL_HIGH>,
				     <0 153 IRQ_TYPE_LEVEL_HIGH>,
				     <0 154 IRQ_TYPE_LEVEL_HIGH>,
				     <0 155 IRQ_TYPE_LEVEL_HIGH>;
			clocks = <&psclks ENSEMBLE_ADC24_CLK>;
			clock-names = "adc_clk";
			status = "disabled";
		};

		cmp0: comparator@49023000 {
			compatible = "alif,cmp-module";
			reg = <0x49023000 0x1000>;
			reg-names = "cmp_reg";
			interrupt-parent = <&gic>;
			interrupts = <0 156 IRQ_TYPE_LEVEL_HIGH>;
			clocks = <&psclks ENSEMBLE_CMP0_CLK>;
			led-gpios = <&port13 0 GPIO_ACTIVE_HIGH>;
			instance = <0>;
			status = "disabled";
		};

		cmp1: comparator@49024000 {
			compatible = "alif,cmp-module";
			reg = <0x49024000 0x1000>;
			reg-names = "cmp_reg";
			interrupt-parent = <&gic>;
			interrupts = <0 157 IRQ_TYPE_LEVEL_HIGH>;
			clocks = <&psclks ENSEMBLE_CMP1_CLK>;
			instance = <1>;
			status = "disabled";
		};

		cmp2: comparator@49025000 {
			compatible = "alif,cmp-module";
			reg = <0x49025000 0x1000>;
			reg-names = "cmp_reg";
			interrupt-parent = <&gic>;
			interrupts = <0 158 IRQ_TYPE_LEVEL_HIGH>;
			clocks = <&psclks ENSEMBLE_CMP2_CLK>;
			instance = <2>;
			status = "disabled";
		};

		cmp3: comparator@49026000 {
			compatible = "alif,cmp-module";
			reg = <0x49026000 0x1000>;
			reg-names = "cmp_reg";
			interrupt-parent = <&gic>;
			interrupts = <0 159 IRQ_TYPE_LEVEL_HIGH>;
			clocks = <&psclks ENSEMBLE_CMP3_CLK>;
			instance = <3>;
			status = "disabled";
		};

		dac12_0: dac@49028000 {
			compatible = "alif,ensemble-dac";
			reg = <0x49028000 0x10>;
			clocks = <&psclks ENSEMBLE_DAC120_CLK>,
				<&psclks ENSEMBLE_CMP0_CLK>;
			clock-names = "dac_clk", "cmp_clk";
			status = "disabled";
		};

		dac12_1: dac@49029000 {
			compatible = "alif,ensemble-dac";
			reg = <0x49029000 0x10>;
			clocks = <&psclks ENSEMBLE_DAC121_CLK>,
				<&psclks ENSEMBLE_CMP0_CLK>;
			clock-names = "dac_clk", "cmp_clk";
			status = "disabled";
		};

		psclks:	clock-controller@4902f000 {
			compatible = "alif,ensemble-ccps";
			reg = <0x4902f000 0x1000>;
			#clock-cells = <1>;
			clocks = <&hfxo>, <&pll_clk1>, <&pll_clk3>;
			clock-names = "hfxo", "pll_clk1", "pll_clk3";

			extclk: camera-extclk {
				compatible = "divider-clock";
				#clock-cells = <0>;
				clocks = <&psclks ENSEMBLE_SYST_ACLK>;
				clock-div = <20>;
				clock-output-names = "extclk";
			};
		};

	};
	apb_d: apb@49030000 {
		compatible = "simple-bus";
		#address-cells = <1>;
		#size-cells = <1>;
		reg = <0x49030000 0x00010000>;
		ranges = <>;

		cpi: camera-controller@49030000 {
			compatible = "alif,ensemble-cpi2";
			reg = <0x49030000 0x1000>;
			interrupt-parent = <&gic>;
			interrupts = <GIC_SPI 334 IRQ_TYPE_LEVEL_HIGH>;
			clocks = <&psclks ENSEMBLE_CPI_APB>, <&psclks ENSEMBLE_CSI_PIXCLK>;
			clock-names = "apb_clk", "pix_clk";
			memory-region = <&cpi_buf>;
			status = "disabled";
		};

		cdc200: cdc200@49031000 {
			compatible = "tes,cdc-2.1";
			reg = <0x49031000 0x1000>;
			interrupt-parent = <&gic>;
			interrupts = <GIC_SPI 322 IRQ_TYPE_LEVEL_HIGH>,
				     <GIC_SPI 324 IRQ_TYPE_LEVEL_HIGH>,
				     <GIC_SPI 326 IRQ_TYPE_LEVEL_HIGH>,
				     <GIC_SPI 328 IRQ_TYPE_LEVEL_HIGH>,
				     <GIC_SPI 330 IRQ_TYPE_LEVEL_HIGH>;
			interrupt-names = "scanline", "fifo-warn",
					  "fifo-underrun", "bus-error",
					  "reload";
			clocks = <&psclks ENSEMBLE_CDC200_APB>, <&psclks ENSEMBLE_CDC200_PIXCLK>;
			clock-names = "apb_pclk", "pix_clk";
			status = "disabled";
		};

		dsi: dsi@49032000 {
			compatible = "alif,ensemble-dsi", "snps,dw-mipi-dsi";
			reg = <0x49032000 0x1000>;
			reg-names = "dsi";
			interrupts = <GIC_SPI 332 IRQ_TYPE_LEVEL_HIGH>;
			clocks = <&psclks ENSEMBLE_DSI_APB>,
				 <&psclks ENSEMBLE_MIPI_TXDPHY_CLK>,
				 <&psclks ENSEMBLE_MIPI_PLLREF_CLK>,
				 <&psclks ENSEMBLE_MIPI_BYPASS_CLK>;
			clock-names = "pclk", "tx_clk", "pll_ref_clk",
				      "pll_bypass_clk";
			#address-cells = <1>;
			#size-cells = <0>;
			#phy-cells = <0>;
			alif,dphy = <&dphy>;
			alif,csi-base = <0x49033000>;
			cfg-clk-frequency = <25000000>;
			status = "disabled";
		};

		csi: csi-controller@49033000 {
			compatible = "alif,ensemble-mipi-csi2", "snps,dw-mipi-csi2-v150";
			reg = <0x49033000 0x1000>;
			reg-names = "core";
			phys = <&dphy 1>;
			phy-names = "rx";
			interrupt-parent = <&gic>;
			interrupts = <GIC_SPI 333 IRQ_TYPE_LEVEL_HIGH>;
			clocks = <&psclks ENSEMBLE_CSI_APB>,
				 <&psclks ENSEMBLE_CSI_PIXCLK>;
			clock-names = "per", "pixel";
			status = "disabled";
		};

		i3c0: i3c@49034000 {
			compatible = "snps,dw-i3c-master-1.00a";
			reg = <0x49034000 0x1000>;
			#address-cells = <3>;
			#size-cells = <0>;
			interrupt-parent = <&gic>;
			interrupts = <GIC_SPI 125 IRQ_TYPE_LEVEL_HIGH>;
			clocks = <&psclks ENSEMBLE_I3C_CLK>;
			clock-names = "core" ;
			i2c-scl-hz = <100000>;
/*			i3c-scl-hz = <2000000>;*/
			status = "disabled";
		};

		/* ALIF Event Router */
		event_router: dma-router@49035000 {
			compatible = "alif,event-router";
			reg = <0x49035000 0x1000>;
			#dma-cells = <2>; /* channel, source */
			dma-masters = <&dmac_bus_ns>;
		};

		dphy: dphy@4903f000 {
			compatible = "alif,dphy", "snps,dphy";
			reg = <0x4903f000 0xb0>, <0x1a609008 0x4>;
			reg-names = "soc_regs", "vbat";
			clocks = <&psclks ENSEMBLE_MIPI_RXDPHY_CLK>,
				 <&psclks ENSEMBLE_MIPI_TXDPHY_CLK>,
				 <&psclks ENSEMBLE_MIPI_PLLREF_CLK>;
			clock-names = "rx_clk", "tx_clk", "pll_ref_clk";
			#phy-cells = <1>;
			alif,csi-base = <0x49033000>;
			alif,dsi-base = <0x49032000>;
			cfg-clk-frequency = <25000000>;
			status = "disabled";
		};
	};
	apb_e: apb@49040000 {
		compatible = "simple-bus";
		#address-cells = <1>;
		#size-cells = <1>;
		reg = <0x49040000 0x000c0000>;
		ranges = <>;

		tes_d2d_0: gpu@49040000 {
			reg = <0x49040000 0x1000>;
			compatible = "tes,d2d-1.0";
			interrupt-parent = <&gic>;
			interrupts = <0 321 IRQ_TYPE_LEVEL_HIGH>;
			clocks = <&psclks ENSEMBLE_SYST_ACLK>;
			max-clock-frequency = <400000000>;
			status = "disabled";
		};

		dmac_bus_ns: dma-controller@490a0000 {
			reg = <0x490a0000 0x1000>;
			arm,primecell-periphid = <0x00041330>;
			compatible = "arm,pl330", "arm,primecell";
			interrupt-parent = <&gic>;
			interrupts =    <0 288 IRQ_TYPE_LEVEL_HIGH>,
					<0 289 IRQ_TYPE_LEVEL_HIGH>,
					<0 290 IRQ_TYPE_LEVEL_HIGH>,
					<0 291 IRQ_TYPE_LEVEL_HIGH>,
					<0 292 IRQ_TYPE_LEVEL_HIGH>,
					<0 293 IRQ_TYPE_LEVEL_HIGH>,
					<0 294 IRQ_TYPE_LEVEL_HIGH>,
					<0 295 IRQ_TYPE_LEVEL_HIGH>,
					<0 296 IRQ_TYPE_LEVEL_HIGH>,
					<0 297 IRQ_TYPE_LEVEL_HIGH>,
					<0 298 IRQ_TYPE_LEVEL_HIGH>,
					<0 299 IRQ_TYPE_LEVEL_HIGH>,
					<0 300 IRQ_TYPE_LEVEL_HIGH>,
					<0 301 IRQ_TYPE_LEVEL_HIGH>,
					<0 302 IRQ_TYPE_LEVEL_HIGH>,
					<0 303 IRQ_TYPE_LEVEL_HIGH>,
					<0 304 IRQ_TYPE_LEVEL_HIGH>,
					<0 305 IRQ_TYPE_LEVEL_HIGH>,
					<0 306 IRQ_TYPE_LEVEL_HIGH>,
					<0 307 IRQ_TYPE_LEVEL_HIGH>,
					<0 308 IRQ_TYPE_LEVEL_HIGH>,
					<0 309 IRQ_TYPE_LEVEL_HIGH>,
					<0 310 IRQ_TYPE_LEVEL_HIGH>,
					<0 311 IRQ_TYPE_LEVEL_HIGH>,
					<0 312 IRQ_TYPE_LEVEL_HIGH>,
					<0 313 IRQ_TYPE_LEVEL_HIGH>,
					<0 314 IRQ_TYPE_LEVEL_HIGH>,
					<0 315 IRQ_TYPE_LEVEL_HIGH>,
					<0 316 IRQ_TYPE_LEVEL_HIGH>,
					<0 317 IRQ_TYPE_LEVEL_HIGH>,
					<0 318 IRQ_TYPE_LEVEL_HIGH>,
					<0 319 IRQ_TYPE_LEVEL_HIGH>,
					<0 320 IRQ_TYPE_LEVEL_HIGH>;
			#dma-cells = <1>;
			#dma-channels = <8>;
			#dma-requests = <32>;
			dma-channel-mask = <0x000fffff>;
			clocks = <&psclks ENSEMBLE_DMA_ENA_CLK>;
			clock-names = "apb_pclk";
		};

		/* Ethos-U85 NPU - ARM Driver Stack */
		ethosu_npu: ethosu@49042000 {
			#address-cells = <1>;
			#size-cells = <1>;
			compatible = "arm,ethosu-direct";
			reg = <0x49042000 0x2000>;
			interrupts = <GIC_SPI 355 IRQ_TYPE_LEVEL_HIGH>;
			interrupt-names = "irq";
			clocks = <&psclks ENSEMBLE_SYST_ACLK>, <&psclks ENSEMBLE_SYST_PCLK>;
			clock-names = "core", "apb";
			memory-region = <&ethosu_reserved>;
			sram = <&ethosu_sram>;
			dma-ranges = <0xa2000000 0xa2000000 0x1000000>,
					<0xa3000000 0xa3000000 0x60000>;
			region-cfgs = <0 0 0 0 0 0 0 0>;
			cs-region = <1>;
			status = "disabled";
			ethosu_mem_config {
				compatible = "arm,ethosu-mem-config";
				/* <beats outstanding_read outstanding_write> */
				sram = <0 64 32>;
				ext  = <1 64 32>;
				/* <mem_domain mem_type axi_port> */
				configs = <0 0 1>,
					<0 0 1>,
					<0 0 1>,
					<0 0 1>;
			};
		};
	};
};
